# daric register map
Vendor: cramium
Registers are 32-bit, read-write, reset 0x0 unless marked. A register's access mark holds for its fields unless they carry their own. Offsets are from the block's base; [hi:lo] are bit positions; {n}, {i} and the like mark numbered series.

## GLUECHAIN
Base 0x40054000
0x00 SFR_GCMASK_CR_GCMASK0 — See file:///F:/code/cram-nto/modules/sec/rtl/gluechain.sv
  [31:0] cr_gcmask0 — cr_gcmask read/write control register
0x04 SFR_GCSR_GLUEREG0 — See file:///F:/code/cram-nto/modules/sec/rtl/gluechain.sv
  [31:0] gluereg0 — gluereg read only status register
0x08 SFR_GCRST_GLUERST0 — See file:///F:/code/cram-nto/modules/sec/rtl/gluechain.sv
  [31:0] gluerst0 — gluerst read/write control register
0x0C SFR_GCTEST_GLUETEST0 — See file:///F:/code/cram-nto/modules/sec/rtl/gluechain.sv
  [31:0] gluetest0 — gluetest read/write control register

## MESH
Base 0x40052000
0x00 SFR_MLDRV_CR_MLDRV0 — See file:///F:/code/cram-nto/modules/sec/rtl/mesh.sv
  [31:0] cr_mldrv0 — cr_mldrv read/write control register
0x04 SFR_MLDRV_CR_MLDRV1 — See file:///F:/code/cram-nto/modules/sec/rtl/mesh.sv
  [31:0] cr_mldrv1 — cr_mldrv read/write control register
0x10 SFR_MLIE_CR_MLIE0 — See file:///F:/code/cram-nto/modules/sec/rtl/mesh.sv
  [31:0] cr_mlie0 — cr_mlie read/write control register
0x14 SFR_MLIE_CR_MLIE1 — See file:///F:/code/cram-nto/modules/sec/rtl/mesh.sv
  [31:0] cr_mlie1 — cr_mlie read/write control register
{0x20+4i} SFR_MLSR_SR_MLSR{i} (i=0..7) — See file:///F:/code/cram-nto/modules/sec/rtl/mesh.sv
  [31:0] sr_mlsr{i} — sr_mlsr read only status register

## SENSORC
Base 0x40053000
0x00 SFR_VDMASK0 — See file:///F:/code/cram-nto/modules/sec/rtl/sensorc.sv
  [7:0] cr_vdmask0 — cr_vdmask0 read/write control register
0x04 SFR_VDMASK1 — See file:///F:/code/cram-nto/modules/sec/rtl/sensorc.sv
  [7:0] cr_vdmask1 — cr_vdmask1 read/write control register
0x08 SFR_VDSR — See file:///F:/code/cram-nto/modules/sec/rtl/sensorc.sv
  [7:0] vdflag — vdflag read only status register
0x0C SFR_VDFR — See file:///F:/code/cram-nto/modules/sec/rtl/sensorc.sv
  [7:0] vdflag — vdflag flag register. `1` means event happened, write back `1` in respective bit position to clear the flag
0x10 SFR_LDMASK — See file:///F:/code/cram-nto/modules/sec/rtl/sensorc.sv
  [3:0] cr_ldmask — cr_ldmask read/write control register
0x14 SFR_LDSR — See file:///F:/code/cram-nto/modules/sec/rtl/sensorc.sv
  [3:0] sr_ldsr — sr_ldsr read only status register
0x18 SFR_LDCFG — See file:///F:/code/cram-nto/modules/sec/rtl/sensorc.sv
  [3:0] sfr_ldcfg — sfr_ldcfg read/write control register
{0x20+4i} SFR_VDCFG_CR_VDCFG{i} (i=0..7) — See file:///F:/code/cram-nto/modules/sec/rtl/sensorc.sv
  [3:0] cr_vdcfg{i} — cr_vdcfg read/write control register
0x40 SFR_VDIP_ENA — See file:///F:/code/cram-nto/modules/sec/rtl/sensorc.sv
  [5:0] vdena — vdena read/write control register
0x44 SFR_VDIP_TEST — See file:///F:/code/cram-nto/modules/sec/rtl/sensorc.sv
  [7:0] vdtst — vdtst read/write control register
0x48 SFR_LDIP_TEST — See file:///F:/code/cram-nto/modules/sec/rtl/sensorc.sv
  [3:0] ldtst — ldtst read/write control register
0x4C SFR_LDIP_FD — See file:///F:/code/cram-nto/modules/sec/rtl/sensorc.sv
  [15:0] sfr_ldip_fd — sfr_ldip_fd read/write control register

## AOBUREG
Base 0x40065000
{0x0+4i} SFR_BUREG_CR_BUREGS{i} (i=0..7) — See file:///F:/code/cram-nto/modules/ao/rtl/aobureg.sv
  [31:0] cr_buregs{i} — cr_buregs read/write control register

## AO_SYSCTRL
Base 0x40060000
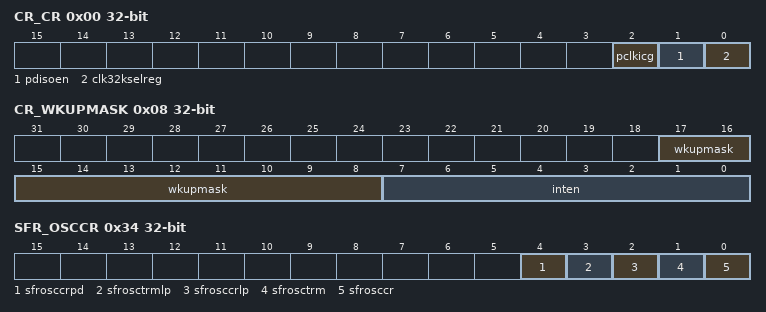
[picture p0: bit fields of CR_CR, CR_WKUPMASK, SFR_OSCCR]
0x00 CR_CR — See file:///F:/code/cram-nto/modules/ao/rtl/ao_sysctrl.sv
  [2] pclkicg — pclkicg read/write control register
  [1] pdisoen — pdisoen read/write control register
  [0] clk32kselreg — clk32kselreg read/write control register
0x04 CR_CLK1HZFD — See file:///F:/code/cram-nto/modules/ao/rtl/ao_sysctrl.sv
  [13:0] cr_clk1hzfd — cr_clk1hzfd read/write control register
0x08 CR_WKUPMASK — See file:///F:/code/cram-nto/modules/ao/rtl/ao_sysctrl.sv
  [17:8] wkupmask — wkupmask read/write control register
  [7:0] inten — inten read/write control register
0x0C CR_RSTCRMASK — See file:///F:/code/cram-nto/modules/ao/rtl/ao_sysctrl.sv
  [4:0] cr_rstcrmask — cr_rstcrmask read/write control register
0x10 SFR_PMUCSR — See file:///F:/code/cram-nto/modules/ao/rtl/ao_sysctrl.sv
  [7:0] pmucrreg — pmucrreg read only status register
0x14 SFR_PMUCRLP — See file:///F:/code/cram-nto/modules/ao/rtl/ao_sysctrl.sv
  [7:0] sfrpmucrlp — sfrpmucrlp read/write control register
0x18 SFR_PMUCRPD — See file:///F:/code/cram-nto/modules/ao/rtl/ao_sysctrl.sv
  [7:0] sfrpmucrpd — sfrpmucrpd read/write control register
0x1C SFR_PMUDFTSR — See file:///F:/code/cram-nto/modules/ao/rtl/ao_sysctrl.sv
  [5:0] pmudftreg — pmudftreg read only status register
0x20 SFR_PMUTRM0CSR — See file:///F:/code/cram-nto/modules/ao/rtl/ao_sysctrl.sv
  [31:0] pmutrmreg — pmutrmreg read only status register
0x24 SFR_PMUTRM1CSR — See file:///F:/code/cram-nto/modules/ao/rtl/ao_sysctrl.sv
  [1:0] pmutrmreg — pmutrmreg read only status register
0x28 SFR_PMUTRMLP0 — See file:///F:/code/cram-nto/modules/ao/rtl/ao_sysctrl.sv
  [31:0] sfrpmutrmlp — sfrpmutrmlp read/write control register
0x2C SFR_PMUTRMLP1 — See file:///F:/code/cram-nto/modules/ao/rtl/ao_sysctrl.sv
  [1:0] sfrpmutrmlp — sfrpmutrmlp read/write control register
0x34 SFR_OSCCR — See file:///F:/code/cram-nto/modules/ao/rtl/ao_sysctrl.sv
  [4] sfrosccrpd — sfrosccrpd read/write control register
  [3] sfrosctrmlp — sfrosctrmlp read/write control register
  [2] sfrosccrlp — sfrosccrlp read/write control register
  [1] sfrosctrm — sfrosctrm read/write control register
  [0] sfrosccr — sfrosccr read/write control register
0x38 SFR_PMUSR — See file:///F:/code/cram-nto/modules/ao/rtl/ao_sysctrl.sv
  [4:0] sfr_pmusr — sfr_pmusr read only status register
0x3C SFR_PMUFR — See file:///F:/code/cram-nto/modules/ao/rtl/ao_sysctrl.sv
  [4:0] sfr_pmufr — sfr_pmufr flag register. `1` means event happened, write back `1` in respective bit position to clear the flag
0x40 SFR_AOFR — See file:///F:/code/cram-nto/modules/ao/rtl/ao_sysctrl.sv
  [9:0] sfr_aofr — sfr_aofr flag register. `1` means event happened, write back `1` in respective bit position to clear the flag
0x44 SFR_PMUPDAR — See file:///F:/code/cram-nto/modules/ao/rtl/ao_sysctrl.sv
  [31:0] sfr_pmupdar — sfr_pmupdar performs action on write of value: 0x5a
0x50 AR_AOPERI_CLRINT — See file:///F:/code/cram-nto/modules/ao/rtl/ao_sysctrl.sv
  [31:0] ar_aoperi_clrint — ar_aoperi_clrint performs action on write of value: 0xaa
0x60 SFR_IOX — See file:///F:/code/cram-nto/modules/ao/rtl/ao_sysctrl.sv
  [0] sfr_iox — sfr_iox read/write control register
0x64 SFR_AOPADPU — See file:///F:/code/cram-nto/modules/ao/rtl/ao_sysctrl.sv
  [9:0] sfr_aopadpu — sfr_aopadpu read/write control register
